# USB_USB2SS_INTR_31000460h register map
Vendor: Texas Instruments
Peripheral module from a debugger description file (folder AM275x).
Registers are 32-bit, read-write, reset values left out (the file's numbers can be read two ways) unless marked. A register's access mark holds for its fields unless they carry their own. Offsets are as the file gives them; lines under a group give offsets from that group; [hi:lo] are bit positions; {n}, {i} and the like mark numbered series; 'fields as' and 'values as' point back to an identical list; <NAME> marks a mode.

## USB2SS_INTR
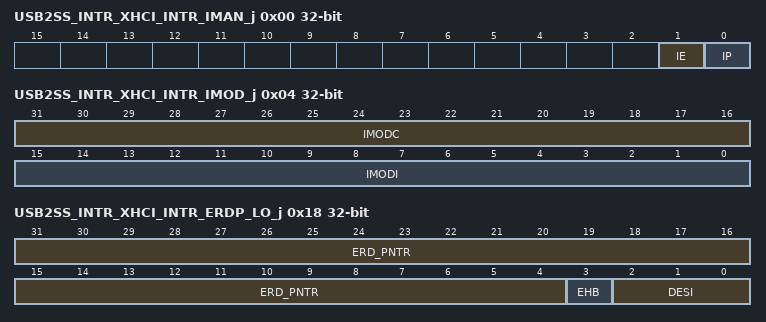
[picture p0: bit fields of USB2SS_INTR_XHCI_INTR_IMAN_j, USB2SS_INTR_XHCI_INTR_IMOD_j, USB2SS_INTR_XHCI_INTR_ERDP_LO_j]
0x00 USB2SS_INTR_XHCI_INTR_IMAN_j access not given — Interrupter Management Register Bit DefinitionsFor a description of this standard USB register field, see the eXtensible Host Controller Interface for Universal Serial Bus (USB) Specification 3.0.
  [1] IE rw — IEFor a description of this standard USB register field, see the eXtensible Host Controller Interface for Universal Serial Bus [USB] Specification 3.0. Reset Source: rst_mod_g_rst_n
  [0] IP — IP Interrupt PendingFor a description of this standard USB register field, see the eXtensible Host Controller Interface for Universal Serial Bus [USB] Specification 3.0. Reset Source: rst_mod_g_rst_n (access R/W1TC)
0x04 USB2SS_INTR_XHCI_INTR_IMOD_j — Interrupter Moderation RegisterThe software may use this register to pace (or even out) the delivery of interrupts to the host CPU. This register provides a guaranteed inter-interrupt delay between interrupts asserted by the xHC, regardless of USB traffic conditions. To independently validate configuration settings, software may use the following algorithm to convert the inter-interrupt Interval value to the common 'interrupts/sec' performance metric.
  [31:16] IMODC — Interrupt Moderation Counter [IMODC] - RW. Default = undefined. Down counter. Loaded with the IMODI value whenever IP is cleared to '0', counts down to '0', and stops. The associated interrupt is signaled whenever this counter is '0', the Event Ring is not empty, the IE and IP flags = '1', and EHB = '0'. This counter may be directly written by software at any time to alter the interrupt rate. Reset Source: rst_mod_g_rst_n
  [15:0] IMODI — Interrupt Moderation Interval [IMODI] - RW. Default = '4000' [~1ms]. Minimum inter-interrupt interval. The interval is specified in 250ns increments. A value of '0' disables interrupt throttling logic and interrupts is generated immediately if IP = '0', EHB = '0', and the Event Ring is not empty. Reset Source: rst_mod_g_rst_n
0x08 USB2SS_INTR_XHCI_INTR_ERSTSZ_j — Event Ring Segment Table Size Register Bit DefinitionsFor a description of this standard USB register field, see the eXtensible Host Controller Interface for Universal Serial Bus (USB) Specification 3.0.
  [15:0] ERS_TABLE_SIZE — ERS_TABLE_SIZEFor a description of this standard USB register field, see the eXtensible Host Controller Interface for Universal Serial Bus [USB] Specification 3.0. Reset Source: rst_mod_g_rst_n
0x0C USB2SS_INTR_XHCI_INTR_RSVDP_j access not given — RsvdP
0x10 USB2SS_INTR_XHCI_INTR_ERSTBA_LO_j — ERSTBA_LO
  [31:6] ERS_TABLE_BAR — ERS_TABLE_BAR Reset Source: rst_mod_g_rst_n
0x14 USB2SS_INTR_XHCI_INTR_ERSTBA_HI_j — ERSTBA_HI
  [31:0] ERS_TABLE_BAR — ERS_TABLE_BARFor a description of this standard USB register field, see the eXtensible Host Controller Interface for Universal Serial Bus [USB] Specification 3.0. Reset Source: rst_mod_g_rst_n
0x18 USB2SS_INTR_XHCI_INTR_ERDP_LO_j access not given — ERDP_LOFor a description of this standard USB register field, see the eXtensible Host Controller Interface for Universal Serial Bus (USB) Specification 3.0.
  [31:4] ERD_PNTR rw — ERD_PNTRFor a description of this standard USB register field, see the eXtensible Host Controller Interface for Universal Serial Bus [USB] Specification 3.0. Reset Source: rst_mod_g_rst_n
  [3] EHB — HC OS Owned SemaphoreERS_TABLE_SIZEHC BIOS Owned Semaphore USB SMI Enable SMI on Host System Error Enable - SMI on OS Ownership Enable - SMI on PCI Command Enable - SMI on BAR Enable - SMI on Event Interrupt - SMI on Host System Error - SMI on OS Ownership Change - SMI on PCI Command - SMI on BAR - Compatible Port Count - HC OS Owned Semaphore - HC BIOS Owned Semaphore - USB SMI Enable - SMI on Host System Error Enable - SMI on OS Ownership Enable - SMI on PCI Command Enable - SMI on BAR Enable - SMI on Event Interrupt - SMI on Host System Error - SMI on OS Ownership Change - SMI on PCI Command - SMI on BAR - Compatible Port Count Reset Source: rst_mod_g_rst_n (access R/W1TC)
  [2:0] DESI rw — DESI - For a description of this standard USB register field, see the eXtensible Host Controller Interface for Universal Serial Bus [USB] Specification 3.0. Reset Source: rst_mod_g_rst_n
0x1C USB2SS_INTR_XHCI_INTR_ERDP_HI_j — ERDP_HI
  [31:0] ERD_PNTR — ERD_PNTRFor a description of this standard USB register field, see the eXtensible Host Controller Interface for Universal Serial Bus [USB] Specification 3.0. Reset Source: rst_mod_g_rst_n
